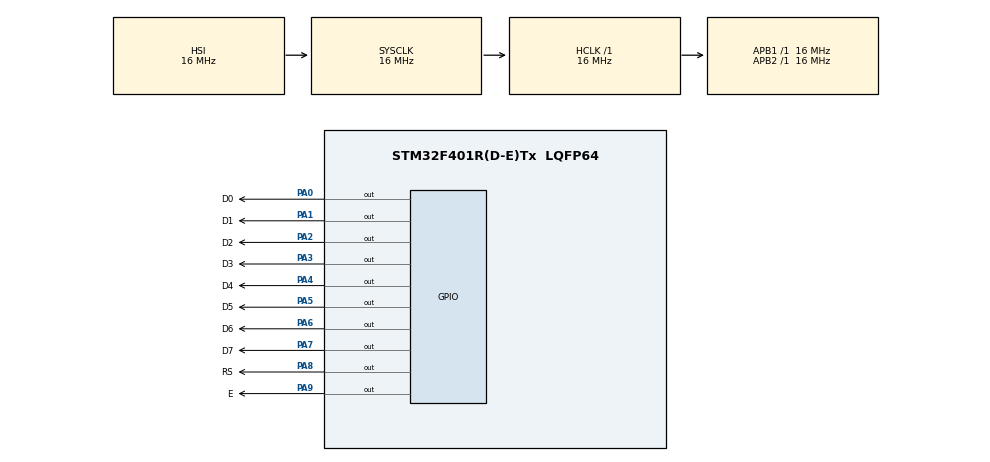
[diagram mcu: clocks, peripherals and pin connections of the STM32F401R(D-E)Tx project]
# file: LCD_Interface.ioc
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Mcu.Family=STM32F4
Mcu.Name=STM32F401R(D-E)Tx
Mcu.Package=LQFP64
NVIC.PriorityGroup=NVIC_PRIORITYGROUP_4
PA0-WKUP.GPIO_Label=D0
PA0-WKUP.Signal=GPIO_Output
PA1.GPIO_Label=D1
PA1.Signal=GPIO_Output
PA2.GPIO_Label=D2
PA2.Signal=GPIO_Output
PA3.GPIO_Label=D3
PA3.Signal=GPIO_Output
PA4.GPIO_Label=D4
PA4.Signal=GPIO_Output
PA5.GPIO_Label=D5
PA5.Signal=GPIO_Output
PA6.GPIO_Label=D6
PA6.Signal=GPIO_Output
PA7.GPIO_Label=D7
PA7.Signal=GPIO_Output
PA8.GPIO_Label=RS
PA8.Signal=GPIO_Output
PA9.GPIO_Label=E
PA9.Signal=GPIO_Output
ProjectManager.HeapSize=0x200
ProjectManager.StackSize=0x400
ProjectManager.TargetToolchain=MDK-ARM V5.27
RCC.AHBFreq_Value=16000000
RCC.APB1Freq_Value=16000000
RCC.APB2Freq_Value=16000000
RCC.CortexFreq_Value=16000000
RCC.HSE_VALUE=25000000
RCC.HSI_VALUE=16000000
RCC.LSE_VALUE=32768
RCC.SYSCLKFreq_VALUE=16000000
RCC.VCOOutputFreq_Value=192000000
board=custom

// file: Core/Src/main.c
/* USER CODE BEGIN Header */
/**
  ******************************************************************************
  * @file           : main.c
  * @brief          : Main program body
  ******************************************************************************
  * @attention
  *
  * <h2><center>&copy; Copyright (c) 2021 STMicroelectronics.
  * All rights reserved.</center></h2>
  *
  * This software component is licensed by ST under BSD 3-Clause license,
  * the "License"; You may not use this file except in compliance with the
  * License. You may obtain a copy of the License at:
  *                        opensource.org/licenses/BSD-3-Clause
  *
  ******************************************************************************
  */
/* USER CODE END Header */
#include "main.h"
#include "STM_MY_LCD16X2.h"
/* USER CODE BEGIN Includes */
//void  LCD_init();
//void LCD(uint8_t val_1, uint8_t cmd);
/* USER CODE END Includes */

void SystemClock_Config(void);
static void MX_GPIO_Init(void);

int main(void)
{

  /* MCU Configuration--------------------------------------------------------*/

  /* Reset of all peripherals, Initializes the Flash interface and the Systick. */
  HAL_Init();

  /* USER CODE BEGIN Init */
//	uint8_t LCD_val;
//	uint8_t str[]={"STM32 TUTORIALS"};
//	uint8_t str1[]={"EMBEDDED SYSTEMS"};
  /* USER CODE END Init */

  /* Configure the system clock */
  SystemClock_Config();

  /* Initialize all configured peripherals */
  MX_GPIO_Init();

	LCD1602_Begin8BIT(RS_GPIO_Port,RS_Pin,E_Pin,D0_GPIO_Port,D0_Pin,D1_Pin,D2_Pin,D3_Pin,D4_GPIO_Port,D4_Pin,D5_Pin,D6_Pin,D7_Pin);

  while (1)
	{
	  LCD1602_print("hello world");
		LCD1602_2ndLine();
		LCD1602_print("Sunil pawar");
		HAL_Delay(100);
		LCD1602_clear();
		LCD1602_print("FERNHILL TECHNOLOGY");
		HAL_Delay(100);
		LCD1602_2ndLine();
		LCD1602_print("STM32F4 TUTORIAL");
		HAL_Delay(100);
    LCD1602_clear();

  }

}

void SystemClock_Config(void)
{
  RCC_OscInitTypeDef RCC_OscInitStruct = {0};
  RCC_ClkInitTypeDef RCC_ClkInitStruct = {0};

  /** Configure the main internal regulator output voltage
  */
  __HAL_RCC_PWR_CLK_ENABLE();
  __HAL_PWR_VOLTAGESCALING_CONFIG(PWR_REGULATOR_VOLTAGE_SCALE2);
  /** Initializes the RCC Oscillators according to the specified parameters
  * in the RCC_OscInitTypeDef structure.
  */
  RCC_OscInitStruct.OscillatorType = RCC_OSCILLATORTYPE_HSI;
  RCC_OscInitStruct.HSIState = RCC_HSI_ON;
  RCC_OscInitStruct.HSICalibrationValue = RCC_HSICALIBRATION_DEFAULT;
  RCC_OscInitStruct.PLL.PLLState = RCC_PLL_NONE;
  if (HAL_RCC_OscConfig(&RCC_OscInitStruct) != HAL_OK)
  {
    Error_Handler();
  }
  /** Initializes the CPU, AHB and APB buses clocks
  */
  RCC_ClkInitStruct.ClockType = RCC_CLOCKTYPE_HCLK|RCC_CLOCKTYPE_SYSCLK
                              |RCC_CLOCKTYPE_PCLK1|RCC_CLOCKTYPE_PCLK2;
  RCC_ClkInitStruct.SYSCLKSource = RCC_SYSCLKSOURCE_HSI;
  RCC_ClkInitStruct.AHBCLKDivider = RCC_SYSCLK_DIV1;
  RCC_ClkInitStruct.APB1CLKDivider = RCC_HCLK_DIV1;
  RCC_ClkInitStruct.APB2CLKDivider = RCC_HCLK_DIV1;

  if (HAL_RCC_ClockConfig(&RCC_ClkInitStruct, FLASH_LATENCY_0) != HAL_OK)
  {
    Error_Handler();
  }
}

static void MX_GPIO_Init(void)
{
  GPIO_InitTypeDef GPIO_InitStruct = {0};

  /* GPIO Ports Clock Enable */
  __HAL_RCC_GPIOA_CLK_ENABLE();

  /*Configure GPIO pin Output Level */
  HAL_GPIO_WritePin(GPIOA, D0_Pin|D1_Pin|D2_Pin|D3_Pin
                          |D4_Pin|D5_Pin|D6_Pin|D7_Pin
                          |RS_Pin|E_Pin, GPIO_PIN_RESET);

  /*Configure GPIO pins : D0_Pin D1_Pin D2_Pin D3_Pin
                           D4_Pin D5_Pin D6_Pin D7_Pin
                           RS_Pin E_Pin */
  GPIO_InitStruct.Pin = D0_Pin|D1_Pin|D2_Pin|D3_Pin
                          |D4_Pin|D5_Pin|D6_Pin|D7_Pin
                          |RS_Pin|E_Pin;
  GPIO_InitStruct.Mode = GPIO_MODE_OUTPUT_PP;
  GPIO_InitStruct.Pull = GPIO_NOPULL;
  GPIO_InitStruct.Speed = GPIO_SPEED_FREQ_LOW;
  HAL_GPIO_Init(GPIOA, &GPIO_InitStruct);

}

void Error_Handler(void)
{
  __disable_irq();
  while (1)
  {
  }
}

/************************ (C) COPYRIGHT STMicroelectronics *****END OF FILE****/
